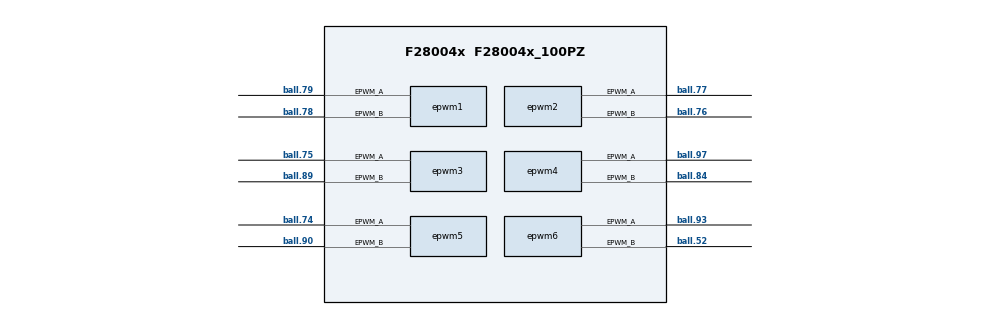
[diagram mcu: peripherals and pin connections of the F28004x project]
/**
 * @cliArgs --device "F28004x" --package "F28004x_100PZ" --part "F28004x_100PZ" --product "C2000WARE@3.01.00.00"
 * @versions {"tool":"1.10.0+2163"}
 */

/**
 * Import the modules used in this configuration.
 */
const epwm  = scripting.addModule("/driverlib/epwm.js", {}, false);
const epwm1 = epwm.addInstance();
const epwm2 = epwm.addInstance();
const epwm3 = epwm.addInstance();
const epwm4 = epwm.addInstance();
const epwm5 = epwm.addInstance();
const epwm6 = epwm.addInstance();

/**
 * Write custom configuration values to the imported modules.
 */
epwm1.$name                  = "myEPWM1";
epwm1.epwm.$assign           = "EPWM1";
epwm1.epwm.epwm_aPin.$assign = "ball.79";
epwm1.epwm.epwm_bPin.$assign = "ball.78";

epwm2.$name                  = "myEPWM2";
epwm2.epwm.$assign           = "EPWM2";
epwm2.epwm.epwm_aPin.$assign = "ball.77";
epwm2.epwm.epwm_bPin.$assign = "ball.76";

epwm3.$name                  = "myEPWM3";
epwm3.epwm.$assign           = "EPWM3";
epwm3.epwm.epwm_aPin.$assign = "ball.75";
epwm3.epwm.epwm_bPin.$assign = "ball.89";

epwm4.$name                  = "myEPWM4";
epwm4.epwm.$assign           = "EPWM4";
epwm4.epwm.epwm_aPin.$assign = "ball.97";
epwm4.epwm.epwm_bPin.$assign = "ball.84";

epwm5.$name                  = "myEPWM5";
epwm5.epwm.$assign           = "EPWM5";
epwm5.epwm.epwm_aPin.$assign = "ball.74";
epwm5.epwm.epwm_bPin.$assign = "ball.90";

epwm6.$name                  = "myEPWM6";
epwm6.epwm.$assign           = "EPWM6";
epwm6.epwm.epwm_aPin.$assign = "ball.93";
epwm6.epwm.epwm_bPin.$assign = "ball.52";
